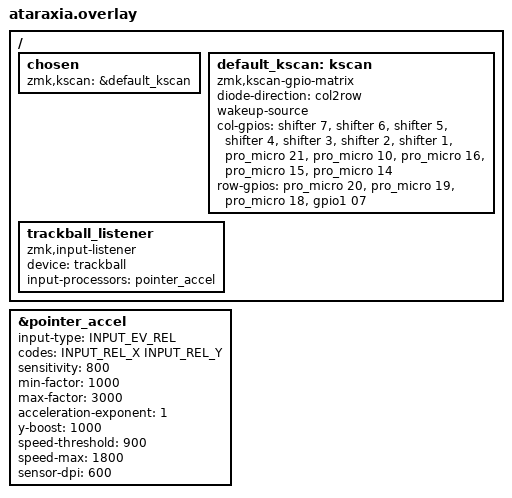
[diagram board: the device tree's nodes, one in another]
#include "ataraxia.dtsi"
#include <input/processors.dtsi>
#include <dt-bindings/zmk/input_transform.h>




/ {
    chosen {
        zmk,kscan = &default_kscan;	
    };

    default_kscan: kscan {
        compatible = "zmk,kscan-gpio-matrix";
        // label = "default_kscan";
        diode-direction = "col2row";                                                                                                                                                                                                               
        wakeup-source;
        col-gpios
            = <&shifter 7 GPIO_ACTIVE_HIGH> // COL0
            , <&shifter 6 GPIO_ACTIVE_HIGH> // COL1
            , <&shifter 5 GPIO_ACTIVE_HIGH> // COL2
            , <&shifter 4 GPIO_ACTIVE_HIGH> // COL3
            , <&shifter 3 GPIO_ACTIVE_HIGH> // COL4
            , <&shifter 2 GPIO_ACTIVE_HIGH> // COL5
            , <&shifter 1 GPIO_ACTIVE_HIGH> // COL7
            , <&pro_micro 21 (GPIO_ACTIVE_HIGH | GPIO_PULL_DOWN)> // COL6
          //  , <&gpio1 01 (GPIO_ACTIVE_HIGH | GPIO_PULL_DOWN)> // COL7        
            , <&pro_micro 10 (GPIO_ACTIVE_HIGH | GPIO_PULL_DOWN)> // COL8
            , <&pro_micro 16 (GPIO_ACTIVE_HIGH | GPIO_PULL_DOWN)> // COL9
            , <&pro_micro 15 (GPIO_ACTIVE_HIGH | GPIO_PULL_DOWN)> // COL10
            , <&pro_micro 14 (GPIO_ACTIVE_HIGH | GPIO_PULL_DOWN)> // COL11
            ;
        row-gpios
            = <&pro_micro 20 (GPIO_ACTIVE_HIGH | GPIO_PULL_DOWN)> // ROW0
            , <&pro_micro 19 (GPIO_ACTIVE_HIGH | GPIO_PULL_DOWN)> // ROW1
            , <&pro_micro 18 (GPIO_ACTIVE_HIGH | GPIO_PULL_DOWN)> // ROW2
            , <&gpio1 07 (GPIO_ACTIVE_HIGH | GPIO_PULL_DOWN)> // ROW3     &shifter 1 
            ;
    };

};

#include <behaviors/input_gestures_accel.dtsi>

&pointer_accel { // this needs to be put BEFORE input-listener
    input-type = <INPUT_EV_REL>;
    codes = <INPUT_REL_X INPUT_REL_Y>;
    sensitivity = <800>;         // 0.8x base sensitivity
	min-factor = <800>;			  // 0.8x minimum for percision
    max-factor = <3000>;          // 3.0x maximum acceleration
    acceleration-exponent = <1>;  // Advanced exponential curve (1-5)
    y-boost = <1000>;             // 1.0x Y-axis boost for widescreen
    speed-threshold = <900>;      // Start acceleration at 900 counts/sec, just 1.5 inch/sec
    speed-max = <1800>;           // Max acceleration at 1800 counts/sec, just 3 inch/sec
    min-factor = <1000>;          // 1.0x minimum (no deceleration)
	sensor-dpi = <600>;
};

/ {
  trackball_listener {
    compatible = "zmk,input-listener";
    status = "okay";
    device = <&trackball>;
    input-processors = <
        &pointer_accel      // Acceleration processor
        >;
  };
};
